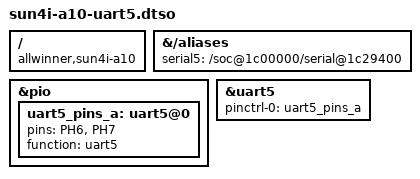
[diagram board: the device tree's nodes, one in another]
/dts-v1/;
/plugin/;

/ {
	compatible = "allwinner,sun4i-a10";

	fragment@0 {
		target-path = "/aliases";
		__overlay__ {
			serial5 = "/soc@1c00000/serial@1c29400";
		};
	};

	fragment@1 {
		target = <&pio>;
		__overlay__ {
			uart5_pins_a: uart5@0 {
				pins = "PH6", "PH7";
				function = "uart5";
			};
		};
	};

	fragment@2 {
		target = <&uart5>;
		 __overlay__ {
			pinctrl-names = "default";
			pinctrl-0 = <&uart5_pins_a>;
			status = "okay";
		};
	};
};
